AUTOSAR XML (schema 4-0-3)
standard types defined: Boolean, UInt32, UInt8
package /AUTOSAR_Platform/DataConstrs
  range DC_Boolean: raw 0..1
package /PATAC/Facility/DataTypes/Implementation
  unit NoUnit: factor-si-to-unit=1, offset-si-to-unit=0
package /PATAC/MSM/ComponentTypes
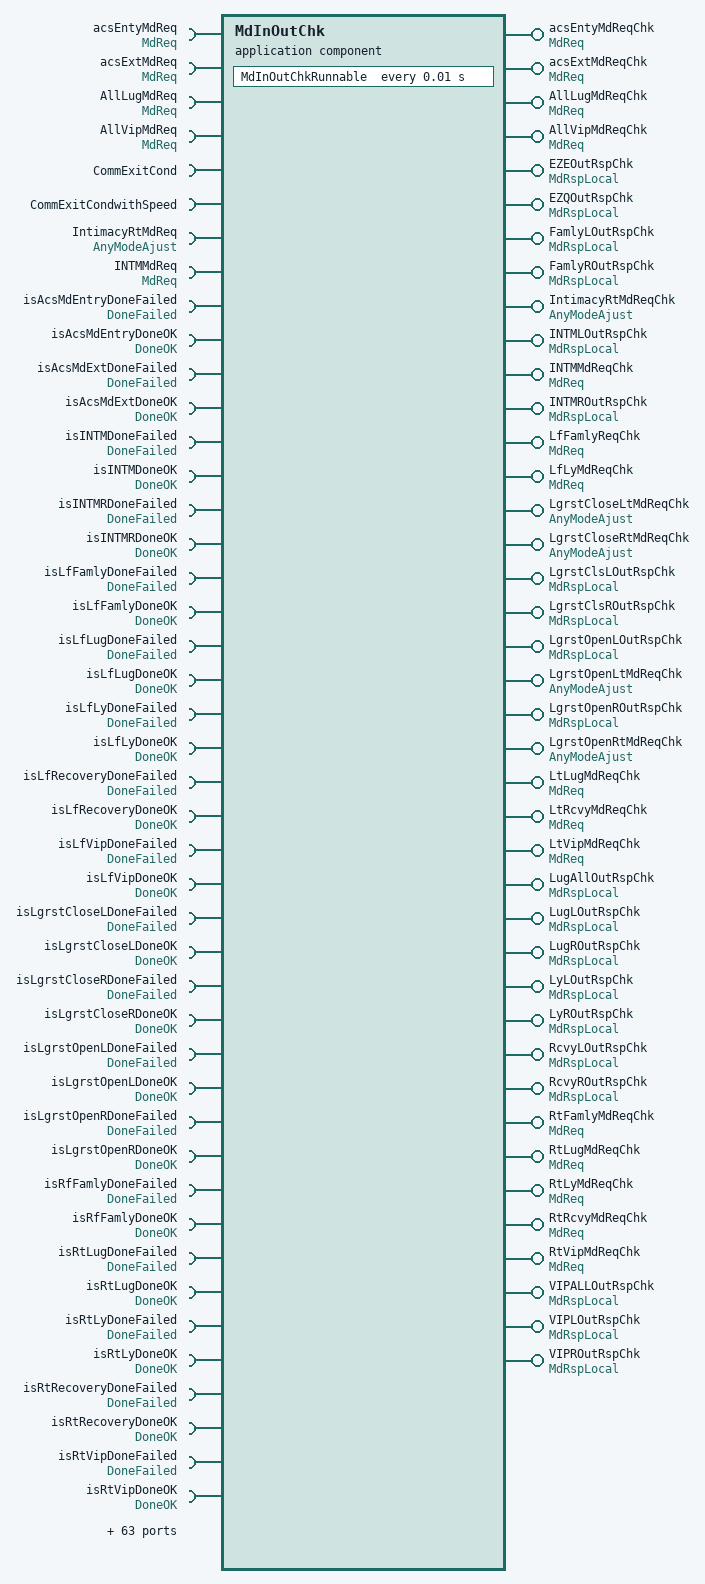
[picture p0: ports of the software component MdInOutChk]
  application sw component type MdInOutChk
    40 x provide port:
      acsEntyMdReqChk: nonqueued-sender-com-spec=data-element=MdReq/Val, provided-interface=MdReq
      acsExtMdReqChk: nonqueued-sender-com-spec=data-element=MdReq/Val, provided-interface=MdReq
      AllLugMdReqChk: nonqueued-sender-com-spec=data-element=MdReq/Val, provided-interface=MdReq
      AllVipMdReqChk: nonqueued-sender-com-spec=data-element=MdReq/Val, provided-interface=MdReq
      EZEOutRspChk: nonqueued-sender-com-spec=data-element=MdRspLocal/Val, provided-interface=MdRspLocal
      EZQOutRspChk: nonqueued-sender-com-spec=data-element=MdRspLocal/Val, provided-interface=MdRspLocal
      FamlyLOutRspChk: nonqueued-sender-com-spec=data-element=MdRspLocal/Val, provided-interface=MdRspLocal
      FamlyROutRspChk: nonqueued-sender-com-spec=data-element=MdRspLocal/Val, provided-interface=MdRspLocal
      IntimacyRtMdReqChk: nonqueued-sender-com-spec=data-element=AnyModeAjust/Val, provided-interface=AnyModeAjust
      INTMLOutRspChk: nonqueued-sender-com-spec=data-element=MdRspLocal/Val, provided-interface=MdRspLocal
      INTMMdReqChk: nonqueued-sender-com-spec=data-element=MdReq/Val, provided-interface=MdReq
      INTMROutRspChk: nonqueued-sender-com-spec=data-element=MdRspLocal/Val, provided-interface=MdRspLocal
      LfFamlyReqChk: nonqueued-sender-com-spec=data-element=MdReq/Val, provided-interface=MdReq
      LfLyMdReqChk: nonqueued-sender-com-spec=data-element=MdReq/Val, provided-interface=MdReq
      LgrstCloseLtMdReqChk: nonqueued-sender-com-spec=data-element=AnyModeAjust/Val, provided-interface=AnyModeAjust
      LgrstCloseRtMdReqChk: nonqueued-sender-com-spec=data-element=AnyModeAjust/Val, provided-interface=AnyModeAjust
      LgrstClsLOutRspChk: nonqueued-sender-com-spec=data-element=MdRspLocal/Val, provided-interface=MdRspLocal
      LgrstClsROutRspChk: nonqueued-sender-com-spec=data-element=MdRspLocal/Val, provided-interface=MdRspLocal
      LgrstOpenLOutRspChk: nonqueued-sender-com-spec=data-element=MdRspLocal/Val, provided-interface=MdRspLocal
      LgrstOpenLtMdReqChk: nonqueued-sender-com-spec=data-element=AnyModeAjust/Val, provided-interface=AnyModeAjust
      LgrstOpenROutRspChk: nonqueued-sender-com-spec=data-element=MdRspLocal/Val, provided-interface=MdRspLocal
      LgrstOpenRtMdReqChk: nonqueued-sender-com-spec=data-element=AnyModeAjust/Val, provided-interface=AnyModeAjust
      LtLugMdReqChk: nonqueued-sender-com-spec=data-element=MdReq/Val, provided-interface=MdReq
      LtRcvyMdReqChk: nonqueued-sender-com-spec=data-element=MdReq/Val, provided-interface=MdReq
      LtVipMdReqChk: nonqueued-sender-com-spec=data-element=MdReq/Val, provided-interface=MdReq
      LugAllOutRspChk: nonqueued-sender-com-spec=data-element=MdRspLocal/Val, provided-interface=MdRspLocal
      LugLOutRspChk: nonqueued-sender-com-spec=data-element=MdRspLocal/Val, provided-interface=MdRspLocal
      LugROutRspChk: nonqueued-sender-com-spec=data-element=MdRspLocal/Val, provided-interface=MdRspLocal
      LyLOutRspChk: nonqueued-sender-com-spec{data-element=MdRspLocal/Val, init-value=0}, provided-interface=MdRspLocal
      LyROutRspChk: nonqueued-sender-com-spec=data-element=MdRspLocal/Val, provided-interface=MdRspLocal
      RcvyLOutRspChk: nonqueued-sender-com-spec=data-element=MdRspLocal/Val, provided-interface=MdRspLocal
      RcvyROutRspChk: nonqueued-sender-com-spec=data-element=MdRspLocal/Val, provided-interface=MdRspLocal
      RtFamlyMdReqChk: nonqueued-sender-com-spec=data-element=MdReq/Val, provided-interface=MdReq
      RtLugMdReqChk: nonqueued-sender-com-spec=data-element=MdReq/Val, provided-interface=MdReq
      RtLyMdReqChk: nonqueued-sender-com-spec=data-element=MdReq/Val, provided-interface=MdReq
      RtRcvyMdReqChk: nonqueued-sender-com-spec=data-element=MdReq/Val, provided-interface=MdReq
      RtVipMdReqChk: nonqueued-sender-com-spec=data-element=MdReq/Val, provided-interface=MdReq
      VIPALLOutRspChk: nonqueued-sender-com-spec=data-element=MdRspLocal/Val, provided-interface=MdRspLocal
      VIPLOutRspChk: nonqueued-sender-com-spec=data-element=MdRspLocal/Val, provided-interface=MdRspLocal
      VIPROutRspChk: nonqueued-sender-com-spec=data-element=MdRspLocal/Val, provided-interface=MdRspLocal
    107 x require port:
      acsEntyMdReq: nonqueued-receiver-com-spec{data-element=MdReq/Val, filter=data-filter-type=ALWAYS, init-value=0}, required-interface=MdReq
      acsExtMdReq: nonqueued-receiver-com-spec{data-element=MdReq/Val, filter=data-filter-type=ALWAYS, init-value=0}, required-interface=MdReq
      AllLugMdReq: nonqueued-receiver-com-spec{data-element=MdReq/Val, filter=data-filter-type=ALWAYS, init-value=0}, required-interface=MdReq
      AllVipMdReq: nonqueued-receiver-com-spec{data-element=MdReq/Val, filter=data-filter-type=ALWAYS, init-value=0}, required-interface=MdReq
      CommExitCond: nonqueued-receiver-com-spec{data-element=CommExitCond/Val, filter=data-filter-type=ALWAYS, init-value=0}, required-interface=CommExitCond
      CommExitCondwithSpeed: nonqueued-receiver-com-spec{data-element=CommExitCondwithSpeed/Val, filter=data-filter-type=ALWAYS, init-value=0}, required-interface=CommExitCondwithSpeed
      IntimacyRtMdReq: nonqueued-receiver-com-spec{data-element=AnyModeAjust/Val, filter=data-filter-type=ALWAYS, init-value=0}, required-interface=AnyModeAjust
      INTMMdReq: nonqueued-receiver-com-spec{data-element=MdReq/Val, filter=data-filter-type=ALWAYS, init-value=0}, required-interface=MdReq
      isAcsMdEntryDoneFailed: nonqueued-receiver-com-spec{data-element=DoneFailed/Val, filter=data-filter-type=ALWAYS, init-value=0}, required-interface=DoneFailed
      isAcsMdEntryDoneOK: nonqueued-receiver-com-spec{data-element=DoneOK/Val, filter=data-filter-type=ALWAYS, init-value=0}, required-interface=DoneOK
      isAcsMdExtDoneFailed: nonqueued-receiver-com-spec{data-element=DoneFailed/Val, filter=data-filter-type=ALWAYS, init-value=0}, required-interface=DoneFailed
      isAcsMdExtDoneOK: nonqueued-receiver-com-spec{data-element=DoneOK/Val, filter=data-filter-type=ALWAYS, init-value=0}, required-interface=DoneOK
      isINTMDoneFailed: nonqueued-receiver-com-spec{data-element=DoneFailed/Val, filter=data-filter-type=ALWAYS, init-value=0}, required-interface=DoneFailed
      isINTMDoneOK: nonqueued-receiver-com-spec{data-element=DoneOK/Val, filter=data-filter-type=ALWAYS, init-value=0}, required-interface=DoneOK
      isINTMRDoneFailed: nonqueued-receiver-com-spec{data-element=DoneFailed/Val, filter=data-filter-type=ALWAYS, init-value=0}, required-interface=DoneFailed
      isINTMRDoneOK: nonqueued-receiver-com-spec{data-element=DoneOK/Val, filter=data-filter-type=ALWAYS, init-value=0}, required-interface=DoneOK
      isLfFamlyDoneFailed: nonqueued-receiver-com-spec{data-element=DoneFailed/Val, filter=data-filter-type=ALWAYS, init-value=0}, required-interface=DoneFailed
      isLfFamlyDoneOK: nonqueued-receiver-com-spec{data-element=DoneOK/Val, filter=data-filter-type=ALWAYS, init-value=0}, required-interface=DoneOK
      isLfLugDoneFailed: nonqueued-receiver-com-spec{data-element=DoneFailed/Val, filter=data-filter-type=ALWAYS, init-value=0}, required-interface=DoneFailed
      isLfLugDoneOK: nonqueued-receiver-com-spec{data-element=DoneOK/Val, filter=data-filter-type=ALWAYS, init-value=0}, required-interface=DoneOK
      isLfLyDoneFailed: nonqueued-receiver-com-spec{data-element=DoneFailed/Val, filter=data-filter-type=ALWAYS, init-value=0}, required-interface=DoneFailed
      isLfLyDoneOK: nonqueued-receiver-com-spec{data-element=DoneOK/Val, filter=data-filter-type=ALWAYS, init-value=0}, required-interface=DoneOK
      isLfRecoveryDoneFailed: nonqueued-receiver-com-spec{data-element=DoneFailed/Val, filter=data-filter-type=ALWAYS, init-value=0}, required-interface=DoneFailed
      isLfRecoveryDoneOK: nonqueued-receiver-com-spec{data-element=DoneOK/Val, filter=data-filter-type=ALWAYS, init-value=0}, required-interface=DoneOK
      isLfVipDoneFailed: nonqueued-receiver-com-spec{data-element=DoneFailed/Val, filter=data-filter-type=ALWAYS, init-value=0}, required-interface=DoneFailed
      isLfVipDoneOK: nonqueued-receiver-com-spec{data-element=DoneOK/Val, filter=data-filter-type=ALWAYS, init-value=0}, required-interface=DoneOK
      isLgrstCloseLDoneFailed: nonqueued-receiver-com-spec{data-element=DoneFailed/Val, filter=data-filter-type=ALWAYS, init-value=0}, required-interface=DoneFailed
      isLgrstCloseLDoneOK: nonqueued-receiver-com-spec{data-element=DoneOK/Val, filter=data-filter-type=ALWAYS, init-value=0}, required-interface=DoneOK
      isLgrstCloseRDoneFailed: nonqueued-receiver-com-spec{data-element=DoneFailed/Val, filter=data-filter-type=ALWAYS, init-value=0}, required-interface=DoneFailed
      isLgrstCloseRDoneOK: nonqueued-receiver-com-spec{data-element=DoneOK/Val, filter=data-filter-type=ALWAYS, init-value=0}, required-interface=DoneOK
      isLgrstOpenLDoneFailed: nonqueued-receiver-com-spec{data-element=DoneFailed/Val, filter=data-filter-type=ALWAYS, init-value=0}, required-interface=DoneFailed
      isLgrstOpenLDoneOK: nonqueued-receiver-com-spec{data-element=DoneOK/Val, filter=data-filter-type=ALWAYS, init-value=0}, required-interface=DoneOK
      isLgrstOpenRDoneFailed: nonqueued-receiver-com-spec{data-element=DoneFailed/Val, filter=data-filter-type=ALWAYS, init-value=0}, required-interface=DoneFailed
      isLgrstOpenRDoneOK: nonqueued-receiver-com-spec{data-element=DoneOK/Val, filter=data-filter-type=ALWAYS, init-value=0}, required-interface=DoneOK
      isRfFamlyDoneFailed: nonqueued-receiver-com-spec{data-element=DoneFailed/Val, filter=data-filter-type=ALWAYS, init-value=0}, required-interface=DoneFailed
      isRfFamlyDoneOK: nonqueued-receiver-com-spec{data-element=DoneOK/Val, filter=data-filter-type=ALWAYS, init-value=0}, required-interface=DoneOK
      isRtLugDoneFailed: nonqueued-receiver-com-spec{data-element=DoneFailed/Val, filter=data-filter-type=ALWAYS, init-value=0}, required-interface=DoneFailed
      isRtLugDoneOK: nonqueued-receiver-com-spec{data-element=DoneOK/Val, filter=data-filter-type=ALWAYS, init-value=0}, required-interface=DoneOK
      isRtLyDoneFailed: nonqueued-receiver-com-spec{data-element=DoneFailed/Val, filter=data-filter-type=ALWAYS, init-value=0}, required-interface=DoneFailed
      isRtLyDoneOK: nonqueued-receiver-com-spec{data-element=DoneOK/Val, filter=data-filter-type=ALWAYS, init-value=0}, required-interface=DoneOK
      isRtRecoveryDoneFailed: nonqueued-receiver-com-spec{data-element=DoneFailed/Val, filter=data-filter-type=ALWAYS, init-value=0}, required-interface=DoneFailed
      isRtRecoveryDoneOK: nonqueued-receiver-com-spec{data-element=DoneOK/Val, filter=data-filter-type=ALWAYS, init-value=0}, required-interface=DoneOK
      isRtVipDoneFailed: nonqueued-receiver-com-spec{data-element=DoneFailed/Val, filter=data-filter-type=ALWAYS, init-value=0}, required-interface=DoneFailed
      isRtVipDoneOK: nonqueued-receiver-com-spec{data-element=DoneOK/Val, filter=data-filter-type=ALWAYS, init-value=0}, required-interface=DoneOK
      LfFamlyReq: nonqueued-receiver-com-spec{data-element=MdReq/Val, filter=data-filter-type=ALWAYS, init-value=0}, required-interface=MdReq
      LfLyMdReq: nonqueued-receiver-com-spec{data-element=MdReq/Val, filter=data-filter-type=ALWAYS, init-value=0}, required-interface=MdReq
      LgrstCloseLtMdReq: nonqueued-receiver-com-spec{data-element=AnyModeAjust/Val, filter=data-filter-type=ALWAYS, init-value=0}, required-interface=AnyModeAjust
      LgrstCloseRtMdReq: nonqueued-receiver-com-spec{data-element=AnyModeAjust/Val, filter=data-filter-type=ALWAYS, init-value=0}, required-interface=AnyModeAjust
      LgrstOpenLtMdReq: nonqueued-receiver-com-spec{data-element=AnyModeAjust/Val, filter=data-filter-type=ALWAYS, init-value=0}, required-interface=AnyModeAjust
      LgrstOpenRtMdReq: nonqueued-receiver-com-spec{data-element=AnyModeAjust/Val, filter=data-filter-type=ALWAYS, init-value=0}, required-interface=AnyModeAjust
      LtLugMdReq: nonqueued-receiver-com-spec{data-element=MdReq/Val, filter=data-filter-type=ALWAYS, init-value=0}, required-interface=MdReq
      LtRcvyMdReq: nonqueued-receiver-com-spec{data-element=MdReq/Val, filter=data-filter-type=ALWAYS, init-value=0}, required-interface=MdReq
      LtVipMdReq: nonqueued-receiver-com-spec{data-element=MdReq/Val, filter=data-filter-type=ALWAYS, init-value=0}, required-interface=MdReq
      LugMdLtAvl: nonqueued-receiver-com-spec{data-element=ModeAdjustAvailable/Val, filter=data-filter-type=ALWAYS, init-value=0}, required-interface=ModeAdjustAvailable
      LugMdRtAvl: nonqueued-receiver-com-spec{data-element=ModeAdjustAvailable/Val, filter=data-filter-type=ALWAYS, init-value=0}, required-interface=ModeAdjustAvailable
      modestate32: nonqueued-receiver-com-spec{data-element=modestate32/Val, filter=data-filter-type=ALWAYS, init-value=0}, required-interface=modestate32
      ModeStateOn: nonqueued-receiver-com-spec{data-element=ModeStateOn/Val, filter=data-filter-type=ALWAYS, init-value=0}, required-interface=ModeStateOn
      R3LMdSeatOccupied: nonqueued-receiver-com-spec{data-element=MdSeatOccupied/Val, filter=data-filter-type=ALWAYS, init-value=0}, required-interface=MdSeatOccupied
      R3RMdSeatOccupied: nonqueued-receiver-com-spec{data-element=MdSeatOccupied/Val, filter=data-filter-type=ALWAYS, init-value=0}, required-interface=MdSeatOccupied
      RtFamlyMdReq: nonqueued-receiver-com-spec{data-element=MdReq/Val, filter=data-filter-type=ALWAYS, init-value=0}, required-interface=MdReq
      RtLugMdReq: nonqueued-receiver-com-spec{data-element=MdReq/Val, filter=data-filter-type=ALWAYS, init-value=0}, required-interface=MdReq
      RtLyMdReq: nonqueued-receiver-com-spec{data-element=MdReq/Val, filter=data-filter-type=ALWAYS, init-value=0}, required-interface=MdReq
      RtRcvyMdReq: nonqueued-receiver-com-spec{data-element=MdReq/Val, filter=data-filter-type=ALWAYS, init-value=0}, required-interface=MdReq
      RtVipMdReq: nonqueued-receiver-com-spec{data-element=MdReq/Val, filter=data-filter-type=ALWAYS, init-value=0}, required-interface=MdReq
      SoftIntAcsEnty: nonqueued-receiver-com-spec{data-element=IntEnable/Val, filter=data-filter-type=ALWAYS, init-value=0}, required-interface=IntEnable
      SoftIntAcsExt: nonqueued-receiver-com-spec{data-element=IntEnable/Val, filter=data-filter-type=ALWAYS, init-value=0}, required-interface=IntEnable
      SoftIntAllLug: nonqueued-receiver-com-spec{data-element=IntEnable/Val, filter=data-filter-type=ALWAYS, init-value=0}, required-interface=IntEnable
      SoftIntAllVip: nonqueued-receiver-com-spec{data-element=IntEnable/Val, filter=data-filter-type=ALWAYS, init-value=0}, required-interface=IntEnable
      SoftIntIntimacyRt: nonqueued-receiver-com-spec{data-element=IntEnable/Val, filter=data-filter-type=ALWAYS, init-value=0}, required-interface=IntEnable
      SoftIntINTM: nonqueued-receiver-com-spec{data-element=IntEnable/Val, filter=data-filter-type=ALWAYS, init-value=0}, required-interface=IntEnable
      SoftIntLfFamly: nonqueued-receiver-com-spec{data-element=IntEnable/Val, filter=data-filter-type=ALWAYS, init-value=0}, required-interface=IntEnable
      SoftIntLfLug: nonqueued-receiver-com-spec{data-element=IntEnable/Val, filter=data-filter-type=ALWAYS, init-value=0}, required-interface=IntEnable
      SoftIntLfLy: nonqueued-receiver-com-spec{data-element=IntEnable/Val, filter=data-filter-type=ALWAYS, init-value=0}, required-interface=IntEnable
      SoftIntLfRcvy: nonqueued-receiver-com-spec{data-element=IntEnable/Val, filter=data-filter-type=ALWAYS, init-value=0}, required-interface=IntEnable
      SoftIntLfVip: nonqueued-receiver-com-spec{data-element=IntEnable/Val, filter=data-filter-type=ALWAYS, init-value=0}, required-interface=IntEnable
      SoftIntLgrstCloseLt: nonqueued-receiver-com-spec{data-element=IntEnable/Val, filter=data-filter-type=ALWAYS, init-value=0}, required-interface=IntEnable
      SoftIntLgrstCloseRt: nonqueued-receiver-com-spec{data-element=IntEnable/Val, filter=data-filter-type=ALWAYS, init-value=0}, required-interface=IntEnable
      SoftIntLgrstOpenLt: nonqueued-receiver-com-spec{data-element=IntEnable/Val, filter=data-filter-type=ALWAYS, init-value=0}, required-interface=IntEnable
      SoftIntLgrstOpenRt: nonqueued-receiver-com-spec{data-element=IntEnable/Val, filter=data-filter-type=ALWAYS, init-value=0}, required-interface=IntEnable
      SoftIntRtFamly: nonqueued-receiver-com-spec{data-element=IntEnable/Val, filter=data-filter-type=ALWAYS, init-value=0}, required-interface=IntEnable
      SoftIntRtLug: nonqueued-receiver-com-spec{data-element=IntEnable/Val, filter=data-filter-type=ALWAYS, init-value=0}, required-interface=IntEnable
      SoftIntRtLy: nonqueued-receiver-com-spec{data-element=IntEnable/Val, filter=data-filter-type=ALWAYS, init-value=0}, required-interface=IntEnable
      SoftIntRtRcvy: nonqueued-receiver-com-spec{data-element=IntEnable/Val, filter=data-filter-type=ALWAYS, init-value=0}, required-interface=IntEnable
      SoftIntRtVip: nonqueued-receiver-com-spec{data-element=IntEnable/Val, filter=data-filter-type=ALWAYS, init-value=0}, required-interface=IntEnable
      StNumFlg: required-interface=StNumFlg
        required-com-specs:
          data-element=Is4s, filter=data-filter-type=ALWAYS, init-value=0
          data-element=Is6s, filter=data-filter-type=ALWAYS, init-value=0
          data-element=Is6s7s, filter=data-filter-type=ALWAYS, init-value=0
          data-element=Is7s, filter=data-filter-type=ALWAYS, init-value=0
      SwIntAcsEnty: nonqueued-receiver-com-spec{data-element=IntEnable/Val, filter=data-filter-type=ALWAYS, init-value=0}, required-interface=IntEnable
      SwIntAcsExt: nonqueued-receiver-com-spec{data-element=IntEnable/Val, filter=data-filter-type=ALWAYS, init-value=0}, required-interface=IntEnable
      SwIntAllLug: nonqueued-receiver-com-spec{data-element=IntEnable/Val, filter=data-filter-type=ALWAYS, init-value=0}, required-interface=IntEnable
      SwIntAllVip: nonqueued-receiver-com-spec{data-element=IntEnable/Val, filter=data-filter-type=ALWAYS, init-value=0}, required-interface=IntEnable
      SwIntIntimacyRt: nonqueued-receiver-com-spec{data-element=IntEnable/Val, filter=data-filter-type=ALWAYS, init-value=0}, required-interface=IntEnable
      SwIntINTM: nonqueued-receiver-com-spec{data-element=IntEnable/Val, filter=data-filter-type=ALWAYS, init-value=0}, required-interface=IntEnable
      SwIntLfFamly: nonqueued-receiver-com-spec{data-element=IntEnable/Val, filter=data-filter-type=ALWAYS, init-value=0}, required-interface=IntEnable
      SwIntLfLug: nonqueued-receiver-com-spec{data-element=IntEnable/Val, filter=data-filter-type=ALWAYS, init-value=0}, required-interface=IntEnable
      SwIntLfLy: nonqueued-receiver-com-spec{data-element=IntEnable/Val, filter=data-filter-type=ALWAYS, init-value=0}, required-interface=IntEnable
      SwIntLfRcvy: nonqueued-receiver-com-spec{data-element=IntEnable/Val, filter=data-filter-type=ALWAYS, init-value=0}, required-interface=IntEnable
      SwIntLfVip: nonqueued-receiver-com-spec{data-element=IntEnable/Val, filter=data-filter-type=ALWAYS, init-value=0}, required-interface=IntEnable
      SwIntLgrstCloseLt: nonqueued-receiver-com-spec{data-element=IntEnable/Val, filter=data-filter-type=ALWAYS, init-value=0}, required-interface=IntEnable
      SwIntLgrstCloseRt: nonqueued-receiver-com-spec{data-element=IntEnable/Val, filter=data-filter-type=ALWAYS, init-value=0}, required-interface=IntEnable
      SwIntLgrstOpenLt: nonqueued-receiver-com-spec{data-element=IntEnable/Val, filter=data-filter-type=ALWAYS, init-value=0}, required-interface=IntEnable
      SwIntLgrstOpenRt: nonqueued-receiver-com-spec{data-element=IntEnable/Val, filter=data-filter-type=ALWAYS, init-value=0}, required-interface=IntEnable
      SwIntRtFamly: nonqueued-receiver-com-spec{data-element=IntEnable/Val, filter=data-filter-type=ALWAYS, init-value=0}, required-interface=IntEnable
      SwIntRtLug: nonqueued-receiver-com-spec{data-element=IntEnable/Val, filter=data-filter-type=ALWAYS, init-value=0}, required-interface=IntEnable
      SwIntRtLy: nonqueued-receiver-com-spec{data-element=IntEnable/Val, filter=data-filter-type=ALWAYS, init-value=0}, required-interface=IntEnable
      SwIntRtRcvy: nonqueued-receiver-com-spec{data-element=IntEnable/Val, filter=data-filter-type=ALWAYS, init-value=0}, required-interface=IntEnable
      SwIntRtVip: nonqueued-receiver-com-spec{data-element=IntEnable/Val, filter=data-filter-type=ALWAYS, init-value=0}, required-interface=IntEnable
      VipMdLtAvl: nonqueued-receiver-com-spec{data-element=ModeAdjustAvailable/Val, filter=data-filter-type=ALWAYS, init-value=0}, required-interface=ModeAdjustAvailable
      VipMdRtAvl: nonqueued-receiver-com-spec{data-element=ModeAdjustAvailable/Val, filter=data-filter-type=ALWAYS, init-value=0}, required-interface=ModeAdjustAvailable
    behavior MdInOutChk_InternalBehavior
      timing event TMT_EZEBsyChkRunnable: start-on-event=MdInOutChkRunnable, period=0.01
      runnable MdInOutChkRunnable
        data-receive-point-by-arguments:
          110 x access:
            REC_acsEntyMdReq_Val: accessed-variable=acsEntyMdReq.Val
            REC_acsExtMdReq_Val: accessed-variable=acsExtMdReq.Val
            REC_AllLugMdReq_Val: accessed-variable=AllLugMdReq.Val
            REC_AllVipMdReq_Val: accessed-variable=AllVipMdReq.Val
            REC_CommExitCond_Val: accessed-variable=CommExitCond.Val
            REC_CommExitCondwithSpeed_Val: accessed-variable=CommExitCondwithSpeed.Val
            REC_IntimacyRtMdReq_Val: accessed-variable=IntimacyRtMdReq.Val
            REC_INTMMdReq_Val: accessed-variable=INTMMdReq.Val
            REC_isAcsMdEntryDoneFailed_Val: accessed-variable=isAcsMdEntryDoneFailed.Val
            REC_isAcsMdEntryDoneOK_Val: accessed-variable=isAcsMdEntryDoneOK.Val
            REC_isAcsMdExtDoneFailed_Val: accessed-variable=isAcsMdExtDoneFailed.Val
            REC_isAcsMdExtDoneOK_Val: accessed-variable=isAcsMdExtDoneOK.Val
            REC_isINTMDoneFailed_Val: accessed-variable=isINTMDoneFailed.Val
            REC_isINTMDoneOK_Val: accessed-variable=isINTMDoneOK.Val
            REC_isINTMRDoneFailed_Val: accessed-variable=isINTMRDoneFailed.Val
            REC_isINTMRDoneOK_Val: accessed-variable=isINTMRDoneOK.Val
            REC_isLfFamlyDoneFailed_Val: accessed-variable=isLfFamlyDoneFailed.Val
            REC_isLfFamlyDoneOK_Val: accessed-variable=isLfFamlyDoneOK.Val
            REC_isLfLugDoneFailed_Val: accessed-variable=isLfLugDoneFailed.Val
            REC_isLfLugDoneOK_Val: accessed-variable=isLfLugDoneOK.Val
            REC_isLfLyDoneFailed_Val: accessed-variable=isLfLyDoneFailed.Val
            REC_isLfLyDoneOK_Val: accessed-variable=isLfLyDoneOK.Val
            REC_isLfRecoveryDoneFailed_Val: accessed-variable=isLfRecoveryDoneFailed.Val
            REC_isLfRecoveryDoneOK_Val: accessed-variable=isLfRecoveryDoneOK.Val
            REC_isLfVipDoneFailed_Val: accessed-variable=isLfVipDoneFailed.Val
            REC_isLfVipDoneOK_Val: accessed-variable=isLfVipDoneOK.Val
            REC_isLgrstCloseLDoneFailed_Val: accessed-variable=isLgrstCloseLDoneFailed.Val
            REC_isLgrstCloseLDoneOK_Val: accessed-variable=isLgrstCloseLDoneOK.Val
            REC_isLgrstCloseRDoneFailed_Val: accessed-variable=isLgrstCloseRDoneFailed.Val
            REC_isLgrstCloseRDoneOK_Val: accessed-variable=isLgrstCloseRDoneOK.Val
            REC_isLgrstOpenLDoneFailed_Val: accessed-variable=isLgrstOpenLDoneFailed.Val
            REC_isLgrstOpenLDoneOK_Val: accessed-variable=isLgrstOpenLDoneOK.Val
            REC_isLgrstOpenRDoneFailed_Val: accessed-variable=isLgrstOpenRDoneFailed.Val
            REC_isLgrstOpenRDoneOK_Val: accessed-variable=isLgrstOpenRDoneOK.Val
            REC_isRfFamlyDoneFailed_Val: accessed-variable=isRfFamlyDoneFailed.Val
            REC_isRfFamlyDoneOK_Val: accessed-variable=isRfFamlyDoneOK.Val
            REC_isRtLugDoneFailed_Val: accessed-variable=isRtLugDoneFailed.Val
            REC_isRtLugDoneOK_Val: accessed-variable=isRtLugDoneOK.Val
            REC_isRtLyDoneFailed_Val: accessed-variable=isRtLyDoneFailed.Val
            REC_isRtLyDoneOK_Val: accessed-variable=isRtLyDoneOK.Val
            REC_isRtRecoveryDoneFailed_Val: accessed-variable=isRtRecoveryDoneFailed.Val
            REC_isRtRecoveryDoneOK_Val: accessed-variable=isRtRecoveryDoneOK.Val
            REC_isRtVipDoneFailed_Val: accessed-variable=isRtVipDoneFailed.Val
            REC_isRtVipDoneOK_Val: accessed-variable=isRtVipDoneOK.Val
            REC_LfFamlyReq_Val: accessed-variable=LfFamlyReq.Val
            REC_LfLyMdReq_Val: accessed-variable=LfLyMdReq.Val
            REC_LgrstCloseLtMdReq_Val: accessed-variable=LgrstCloseLtMdReq.Val
            REC_LgrstCloseRtMdReq_Val: accessed-variable=LgrstCloseRtMdReq.Val
            REC_LgrstOpenLtMdReq_Val: accessed-variable=LgrstOpenLtMdReq.Val
            REC_LgrstOpenRtMdReq_Val: accessed-variable=LgrstOpenRtMdReq.Val
            REC_LtLugMdReq_Val: accessed-variable=LtLugMdReq.Val
            REC_LtRcvyMdReq_Val: accessed-variable=LtRcvyMdReq.Val
            REC_LtVipMdReq_Val: accessed-variable=LtVipMdReq.Val
            REC_LugMdLtAvl_Val: accessed-variable=LugMdLtAvl.Val
            REC_LugMdRtAvl_Val: accessed-variable=LugMdRtAvl.Val
            REC_modestate32_Val: accessed-variable=modestate32.Val
            REC_ModeStateOn_Val: accessed-variable=ModeStateOn.Val
            REC_R3LMdSeatOccupied_Val: accessed-variable=R3LMdSeatOccupied.Val
            REC_R3RMdSeatOccupied_Val: accessed-variable=R3RMdSeatOccupied.Val
            REC_RtFamlyMdReq_Val: accessed-variable=RtFamlyMdReq.Val
            REC_RtLugMdReq_Val: accessed-variable=RtLugMdReq.Val
            REC_RtLyMdReq_Val: accessed-variable=RtLyMdReq.Val
            REC_RtRcvyMdReq_Val: accessed-variable=RtRcvyMdReq.Val
            REC_RtVipMdReq_Val: accessed-variable=RtVipMdReq.Val
            REC_SoftIntAcsEnty_Val: accessed-variable=SoftIntAcsEnty.Val
            REC_SoftIntAcsExt_Val: accessed-variable=SoftIntAcsExt.Val
            REC_SoftIntAllLug_Val: accessed-variable=SoftIntAllLug.Val
            REC_SoftIntAllVip_Val: accessed-variable=SoftIntAllVip.Val
            REC_SoftIntIntimacyRt_Val: accessed-variable=SoftIntIntimacyRt.Val
            REC_SoftIntINTM_Val: accessed-variable=SoftIntINTM.Val
            REC_SoftIntLfFamly_Val: accessed-variable=SoftIntLfFamly.Val
            REC_SoftIntLfLug_Val: accessed-variable=SoftIntLfLug.Val
            REC_SoftIntLfLy_Val: accessed-variable=SoftIntLfLy.Val
            REC_SoftIntLfRcvy_Val: accessed-variable=SoftIntLfRcvy.Val
            REC_SoftIntLfVip_Val: accessed-variable=SoftIntLfVip.Val
            REC_SoftIntLgrstCloseLt_Val: accessed-variable=SoftIntLgrstCloseLt.Val
            REC_SoftIntLgrstCloseRt_Val: accessed-variable=SoftIntLgrstCloseRt.Val
            REC_SoftIntLgrstOpenLt_Val: accessed-variable=SoftIntLgrstOpenLt.Val
            REC_SoftIntLgrstOpenRt_Val: accessed-variable=SoftIntLgrstOpenRt.Val
            REC_SoftIntRtFamly_Val: accessed-variable=SoftIntRtFamly.Val
            REC_SoftIntRtLug_Val: accessed-variable=SoftIntRtLug.Val
            REC_SoftIntRtLy_Val: accessed-variable=SoftIntRtLy.Val
            REC_SoftIntRtRcvy_Val: accessed-variable=SoftIntRtRcvy.Val
            REC_SoftIntRtVip_Val: accessed-variable=SoftIntRtVip.Val
            REC_StNumFlg_Is4s: accessed-variable=StNumFlg.Is4s
            REC_StNumFlg_Is6s: accessed-variable=StNumFlg.Is6s
            REC_StNumFlg_Is6s7s: accessed-variable=StNumFlg.Is6s7s
            REC_StNumFlg_Is7s: accessed-variable=StNumFlg.Is7s
            REC_SwIntAcsEnty_Val: accessed-variable=SwIntAcsEnty.Val
            REC_SwIntAcsExt_Val: accessed-variable=SwIntAcsExt.Val
            REC_SwIntAllLug_Val: accessed-variable=SwIntAllLug.Val
            REC_SwIntAllVip_Val: accessed-variable=SwIntAllVip.Val
            REC_SwIntIntimacyRt_Val: accessed-variable=SwIntIntimacyRt.Val
            REC_SwIntINTM_Val: accessed-variable=SwIntINTM.Val
            REC_SwIntLfFamly_Val: accessed-variable=SwIntLfFamly.Val
            REC_SwIntLfLug_Val: accessed-variable=SwIntLfLug.Val
            REC_SwIntLfLy_Val: accessed-variable=SwIntLfLy.Val
            REC_SwIntLfRcvy_Val: accessed-variable=SwIntLfRcvy.Val
            REC_SwIntLfVip_Val: accessed-variable=SwIntLfVip.Val
            REC_SwIntLgrstCloseLt_Val: accessed-variable=SwIntLgrstCloseLt.Val
            REC_SwIntLgrstCloseRt_Val: accessed-variable=SwIntLgrstCloseRt.Val
            REC_SwIntLgrstOpenLt_Val: accessed-variable=SwIntLgrstOpenLt.Val
            REC_SwIntLgrstOpenRt_Val: accessed-variable=SwIntLgrstOpenRt.Val
            REC_SwIntRtFamly_Val: accessed-variable=SwIntRtFamly.Val
            REC_SwIntRtLug_Val: accessed-variable=SwIntRtLug.Val
            REC_SwIntRtLy_Val: accessed-variable=SwIntRtLy.Val
            REC_SwIntRtRcvy_Val: accessed-variable=SwIntRtRcvy.Val
            REC_SwIntRtVip_Val: accessed-variable=SwIntRtVip.Val
            REC_VipMdLtAvl_Val: accessed-variable=VipMdLtAvl.Val
            REC_VipMdRtAvl_Val: accessed-variable=VipMdRtAvl.Val
        data-send-points:
          40 x access:
            SEND_acsEntyMdReqChk_Val: accessed-variable=acsEntyMdReqChk.Val
            SEND_acsExtMdReqChk_Val: accessed-variable=acsExtMdReqChk.Val
            SEND_AllLugMdReqChk_Val: accessed-variable=AllLugMdReqChk.Val
            SEND_AllVipMdReqChk_Val: accessed-variable=AllVipMdReqChk.Val
            SEND_EZEOutRspChk_Val: accessed-variable=EZEOutRspChk.Val
            SEND_EZQOutRspChk_Val: accessed-variable=EZQOutRspChk.Val
            SEND_FamlyLOutRspChk_Val: accessed-variable=FamlyLOutRspChk.Val
            SEND_FamlyROutRspChk_Val: accessed-variable=FamlyROutRspChk.Val
            SEND_IntimacyRtMdReqChk_Val: accessed-variable=IntimacyRtMdReqChk.Val
            SEND_INTMLOutRspChk_Val: accessed-variable=INTMLOutRspChk.Val
            SEND_INTMMdReqChk_Val: accessed-variable=INTMMdReqChk.Val
            SEND_INTMROutRspChk_Val: accessed-variable=INTMROutRspChk.Val
            SEND_LfFamlyReqChk_Val: accessed-variable=LfFamlyReqChk.Val
            SEND_LfLyMdReqChk_Val: accessed-variable=LfLyMdReqChk.Val
            SEND_LgrstCloseLtMdReqChk_Val: accessed-variable=LgrstCloseLtMdReqChk.Val
            SEND_LgrstCloseRtMdReqChk_Val: accessed-variable=LgrstCloseRtMdReqChk.Val
            SEND_LgrstClsLOutRspChk_Val: accessed-variable=LgrstClsLOutRspChk.Val
            SEND_LgrstClsROutRspChk_Val: accessed-variable=LgrstClsROutRspChk.Val
            SEND_LgrstOpenLOutRspChk_Val: accessed-variable=LgrstOpenLOutRspChk.Val
            SEND_LgrstOpenLtMdReqChk_Val: accessed-variable=LgrstOpenLtMdReqChk.Val
            SEND_LgrstOpenROutRspChk_Val: accessed-variable=LgrstOpenROutRspChk.Val
            SEND_LgrstOpenRtMdReqChk_Val: accessed-variable=LgrstOpenRtMdReqChk.Val
            SEND_LtLugMdReqChk_Val: accessed-variable=LtLugMdReqChk.Val
            SEND_LtRcvyMdReqChk_Val: accessed-variable=LtRcvyMdReqChk.Val
            SEND_LtVipMdReqChk_Val: accessed-variable=LtVipMdReqChk.Val
            SEND_LugAllOutRspChk_Val: accessed-variable=LugAllOutRspChk.Val
            SEND_LugLOutRspChk_Val: accessed-variable=LugLOutRspChk.Val
            SEND_LugROutRspChk_Val: accessed-variable=LugROutRspChk.Val
            SEND_LyLOutRspChk_Val: accessed-variable=LyLOutRspChk.Val
            SEND_LyROutRspChk_Val: accessed-variable=LyROutRspChk.Val
            SEND_RcvyLOutRspChk_Val: accessed-variable=RcvyLOutRspChk.Val
            SEND_RcvyROutRspChk_Val: accessed-variable=RcvyROutRspChk.Val
            SEND_RtFamlyMdReqChk_Val: accessed-variable=RtFamlyMdReqChk.Val
            SEND_RtLugMdReqChk_Val: accessed-variable=RtLugMdReqChk.Val
            SEND_RtLyMdReqChk_Val: accessed-variable=RtLyMdReqChk.Val
            SEND_RtRcvyMdReqChk_Val: accessed-variable=RtRcvyMdReqChk.Val
            SEND_RtVipMdReqChk_Val: accessed-variable=RtVipMdReqChk.Val
            SEND_VIPALLOutRspChk_Val: accessed-variable=VIPALLOutRspChk.Val
            SEND_VIPLOutRspChk_Val: accessed-variable=VIPLOutRspChk.Val
            SEND_VIPROutRspChk_Val: accessed-variable=VIPROutRspChk.Val
  swc implementation MdInOutChk_Implementation: behavior=MdInOutChk_InternalBehavior
    code-descriptors:
      code Default: artifact-descriptors=autosar-engineering-object={short-label=Default, category=SWSRC}
package /PATAC/MSM/DataTypes/ImplementationDataTypes
  impl type IntEnable: category=VALUE, base-type=Boolean, sw-calibration-access=READ-ONLY, type-emitter=RTE
package /PATAC/MSM/ModeAdjust/DataType
  impl type MdRspLocal2: category=VALUE, base-type=UInt8, sw-calibration-access=READ-ONLY, compu {0=MdRsp_None, 1=MdRsp_RecallSuccessfully, 2=MdRsp_RecallUnsuccessfully_LocalInterrupt, 3=MdRsp_RecallUnsuccessfully_NonEnghSpace, 4=MdRsp_RecallOngoing, 5=MdRsp_TargetPositionAlready, 6=MdRsp_LowPower, 7=MdRsp_CrashStat, 8=MdRsp_ThdRwOccupt, 9=MdRsp_PosNotLrn, 10=MdRsp_NotParkStat, 11=MdRsp_SpdNotCorrt}, type-emitter=RTE
package /PATAC/MSM/ModeAdjust/PortInterface
  13 x sender receiver interface:
    AnyModeAjust: invalidation-policy{data-element=AnyModeAjust/Val, handle-invalid=DONT-INVALIDATE}
      data Val: type=Boolean
    CommExitCond: invalidation-policy{data-element=CommExitCond/Val, handle-invalid=DONT-INVALIDATE}
      data Val: type=Boolean
    CommExitCondwithSpeed: invalidation-policy{data-element=CommExitCondwithSpeed/Val, handle-invalid=DONT-INVALIDATE}
      data Val: type=Boolean
    DoneFailed: invalidation-policy{data-element=DoneFailed/Val, handle-invalid=DONT-INVALIDATE}
      data Val: type=Boolean
    DoneOK: invalidation-policy{data-element=DoneOK/Val, handle-invalid=DONT-INVALIDATE}
      data Val: type=Boolean
    IntEnable: invalidation-policy{data-element=IntEnable/Val, handle-invalid=DONT-INVALIDATE}
      data Val: type=IntEnable
    MdReq: invalidation-policy{data-element=MdReq/Val, handle-invalid=DONT-INVALIDATE}
      data Val: type=Boolean
    MdRspLocal: invalidation-policy{data-element=MdRspLocal/Val, handle-invalid=DONT-INVALIDATE}
      data Val: type=MdRspLocal2
    MdSeatOccupied: invalidation-policy{data-element=MdSeatOccupied/Val, handle-invalid=DONT-INVALIDATE}
      data Val: type=Boolean
    ModeAdjustAvailable: invalidation-policy{data-element=ModeAdjustAvailable/Val, handle-invalid=DONT-INVALIDATE}
      data Val: type=Boolean
    modestate32: invalidation-policy{data-element=modestate32/Val, handle-invalid=DONT-INVALIDATE}
      data Val: type=UInt32
    ModeStateOn: invalidation-policy{data-element=ModeStateOn/Val, handle-invalid=DONT-INVALIDATE}
      data Val: type=Boolean
    StNumFlg
      4 x data, all with type=Boolean:
        Is4s
        Is6s
        Is6s7s
        Is7s
      invalidation-policys:
        data-element=Is7s, handle-invalid=DONT-INVALIDATE
        data-element=Is6s, handle-invalid=DONT-INVALIDATE
        data-element=Is4s, handle-invalid=DONT-INVALIDATE
        data-element=Is6s7s, handle-invalid=DONT-INVALIDATE
